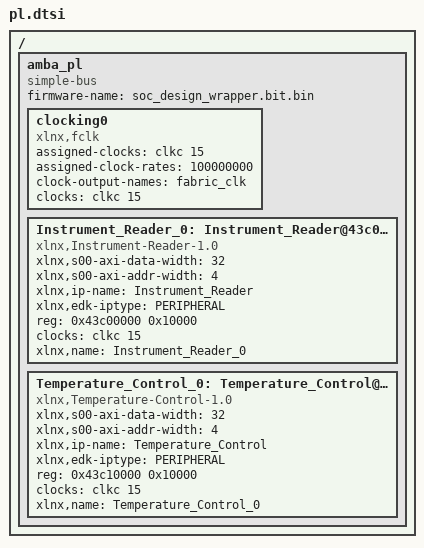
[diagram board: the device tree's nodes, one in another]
/ {
	amba_pl: amba_pl {
		ranges;
		compatible = "simple-bus";
		#address-cells = <1>;
		#size-cells = <1>;
		firmware-name = "soc_design_wrapper.bit.bin";
		clocking0: clocking0 {
			compatible = "xlnx,fclk";
			assigned-clocks = <&clkc 15>;
			assigned-clock-rates = <100000000>;
			#clock-cells = <0>;
			clock-output-names = "fabric_clk";
			clocks = <&clkc 15>;
		};
		Instrument_Reader_0: Instrument_Reader@43c00000 {
			xlnx,s00-axi-data-width = <32>;
			compatible = "xlnx,Instrument-Reader-1.0";
			status = "okay";
			clock-names = "s00_axi_aclk";
			xlnx,s00-axi-addr-width = <4>;
			xlnx,ip-name = "Instrument_Reader";
			xlnx,edk-iptype = "PERIPHERAL";
			reg = <0x43c00000 0x10000>;
			clocks = <&clkc 15>;
			xlnx,name = "Instrument_Reader_0";
		};
		Temperature_Control_0: Temperature_Control@43c10000 {
			xlnx,s00-axi-data-width = <32>;
			compatible = "xlnx,Temperature-Control-1.0";
			status = "okay";
			clock-names = "s00_axi_aclk";
			xlnx,s00-axi-addr-width = <4>;
			xlnx,ip-name = "Temperature_Control";
			xlnx,edk-iptype = "PERIPHERAL";
			reg = <0x43c10000 0x10000>;
			clocks = <&clkc 15>;
			xlnx,name = "Temperature_Control_0";
		};
	};
};
